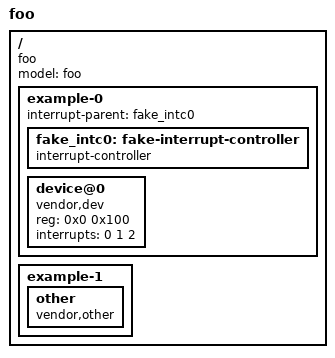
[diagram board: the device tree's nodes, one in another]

/dts-v1/;
/plugin/; // silence any missing phandle references

/{
    compatible = "foo";
    model = "foo";
    #address-cells = <1>;
    #size-cells = <1>;


    example-0 {
        #address-cells = <1>;
        #size-cells = <1>;

        
        interrupt-parent = <&fake_intc0>;
        fake_intc0: fake-interrupt-controller {
            interrupt-controller;
            #interrupt-cells = < 3 >;
        };


        device@0 {
            compatible = "vendor,dev";
            reg = <0x0 0x100>;
            interrupts = <0 1 2>;
        };

    };
};

/{
    compatible = "foo";
    model = "foo";
    #address-cells = <1>;
    #size-cells = <1>;


    example-1 {
        #address-cells = <1>;
        #size-cells = <1>;

        

        other {
            compatible = "vendor,other";
        };

    };
};

